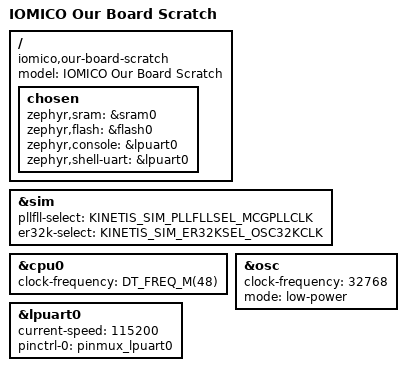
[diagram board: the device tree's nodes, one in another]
/*
 * SPDX-License-Identifier: Apache-2.0
 */

/dts-v1/;

#include <nxp/mcx/mcxc/nxp_mcxc444.dtsi>
#include "our_board_scratch-pinctrl.dtsi"

/ {
	model = "IOMICO Our Board Scratch";
	compatible = "iomico,our-board-scratch", "nxp,mcx";

	chosen {
		zephyr,sram = &sram0;
		zephyr,flash = &flash0;
		zephyr,console = &lpuart0;
		zephyr,shell-uart = &lpuart0;
	};
};

&sim {
	pllfll-select = <KINETIS_SIM_PLLFLLSEL_MCGPLLCLK>;
	er32k-select = <KINETIS_SIM_ER32KSEL_OSC32KCLK>;
};

&cpu0 {
	clock-frequency = <DT_FREQ_M(48)>;
};

&osc {
	clock-frequency = <32768>;
	mode = "low-power";
};

&lpuart0 {
	status = "okay";
	current-speed = <115200>;
	pinctrl-0 = <&pinmux_lpuart0>;
	pinctrl-names = "default";
};
